# USB3SS0_ECC_AGGR register map
Vendor: Texas Instruments
Peripheral module from a debugger description file (folder am65x).
Registers are 32-bit, access not given, reset 0x0 unless marked. A register's access mark holds for its fields unless they carry their own. Offsets are as the file gives them; lines under a group give offsets from that group; [hi:lo] are bit positions; {n}, {i} and the like mark numbered series; 'fields as' and 'values as' point back to an identical list; <NAME> marks a mode.

## USB3SS0_ECC_AGGR
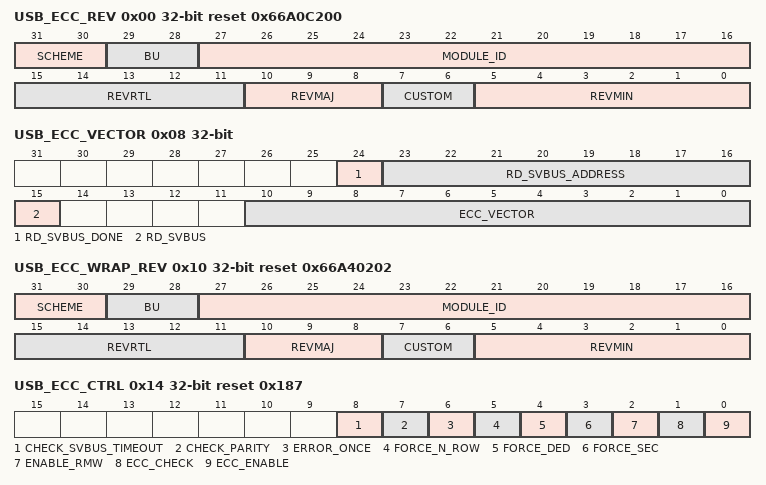
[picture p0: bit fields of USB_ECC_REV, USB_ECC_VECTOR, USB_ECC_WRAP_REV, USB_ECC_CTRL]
0x00 USB_ECC_REV ro reset 0x66A0C200 — Revision parameters
  [31:30] SCHEME
  [29:28] BU
  [27:16] MODULE_ID
  [15:11] REVRTL — RTL version
  [10:8] REVMAJ — Major version
  [7:6] CUSTOM — Custom version
  [5:0] REVMIN — Minor version
0x08 USB_ECC_VECTOR — ECC Vector Register
  [24] RD_SVBUS_DONE ro — Status to indicate if read on serial VBUS is complete
  [23:16] RD_SVBUS_ADDRESS rw — Read address
  [15] RD_SVBUS — Write 1 to trigger a read on the serial VBUS (access RW1S)
  [10:0] ECC_VECTOR rw — Value written to select the corresponding ECC RAM for control or status
0x0C USB_ECC_STAT ro reset 0x3 — Misc Status
  [10:0] NUM_RAMS — Indicates the number of RAMS serviced by the ECC aggregator
0x10 USB_ECC_WRAP_REV ro reset 0x66A40202 — Revision parameters
  fields as USB_ECC_REV
0x14 USB_ECC_CTRL rw reset 0x187 — ECC Control Register
  [8] CHECK_SVBUS_TIMEOUT — check for svbus timeout errors
  [7] CHECK_PARITY — check for parity errors
  [6] ERROR_ONCE — Force Error only once
  [5] FORCE_N_ROW — Force Error on any RAM read
  [4] FORCE_DED — Force Double Bit Error
  [3] FORCE_SEC — Force Single Bit Error
  [2] ENABLE_RMW
  [1] ECC_CHECK — Enable ECC check
  [0] ECC_ENABLE — Enable ECC
0x18 USB_ECC_ERR_CTRL1 rw — ECC Error Control1 Register
  [31:0] ECC_ROW — Row address where single or double-bit error needs to be applied. This is ignored if force_n_row is set
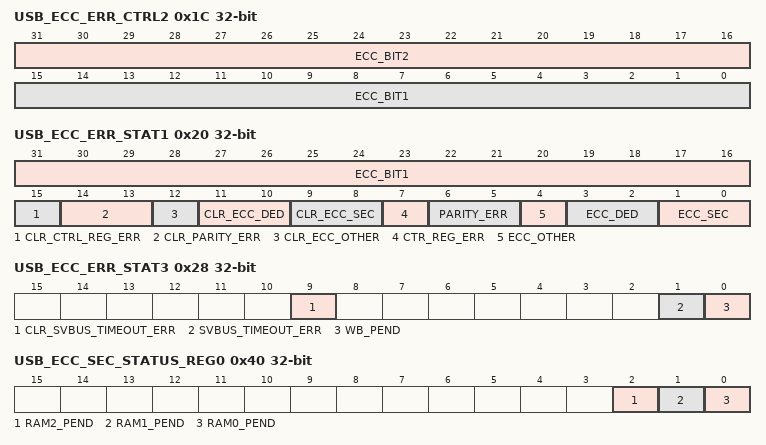
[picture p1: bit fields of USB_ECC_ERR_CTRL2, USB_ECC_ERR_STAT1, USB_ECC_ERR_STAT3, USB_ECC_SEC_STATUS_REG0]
0x1C USB_ECC_ERR_CTRL2 rw — ECC Error Control2 Register
  [31:16] ECC_BIT2 — Data bit that needs to be flipped if double bit error needs to be forced
  [15:0] ECC_BIT1 — Data bit that needs to be flipped when force_sec is set
0x20 USB_ECC_ERR_STAT1 — ECC Error Status1 Register
  [31:16] ECC_BIT1 ro — Data bit that corresponds to the single-bit error
  [15] CLR_CTRL_REG_ERR — Clear control reg error Error Status, one must also re write the contorl ergister itself to clear this (access RW1C)
  [14:13] CLR_PARITY_ERR rw — Clear parity Error Status
  [12] CLR_ECC_OTHER — Clear other Error Status (access RW1C)
  [11:10] CLR_ECC_DED rw — Clear Double Bit Error Status
  [9:8] CLR_ECC_SEC rw — Clear Single Bit Error Status
  [7] CTR_REG_ERR — control register error pending, Level interrupt (access RW1S)
  [6:5] PARITY_ERR — Level parity error Error Status (access RW1S)
  [4] ECC_OTHER — successive single-bit errors have occurred while a writeback is still pending, Level interrupt (access RW1S)
  [3:2] ECC_DED rw — Level Double Bit Error Status
  [1:0] ECC_SEC rw — Level Single Bit Error Status
0x24 USB_ECC_ERR_STAT2 ro — ECC Error Status2 Register
  [31:0] ECC_ROW — Row address where the single or double-bit error has occurred
0x28 USB_ECC_ERR_STAT3 — ECC Error Status3 Register
  [9] CLR_SVBUS_TIMEOUT_ERR — Clear svbus timeout Error Status (access RW1C)
  [1] SVBUS_TIMEOUT_ERR — Level svbus timeout error Error Status (access RW1S)
  [0] WB_PEND ro — delayed write back pending Status
0x3C USB_ECC_SEC_EOI_REG — EOI Register The EOI register is used to re-trigger the pulse interrupt signal to ensure that any nested interrupt events are serviced. The software interrupt handler must write to the EOI register at the end of the current interrupt processing routine, so that new events can re-trigger the pulse interrupt signal again. For level interrupt signals the EOI register is not functional and must not be used.
  [0] EOI_WR — EOI Register (access RW1S)
0x40 USB_ECC_SEC_STATUS_REG0 — Interrupt Status Register 0
  [2] RAM2_PEND — Interrupt Pending Status for ram2_pend (access RW1S)
  [1] RAM1_PEND — Interrupt Pending Status for ram1_pend (access RW1S)
  [0] RAM0_PEND — Interrupt Pending Status for ram0_pend (access RW1S)
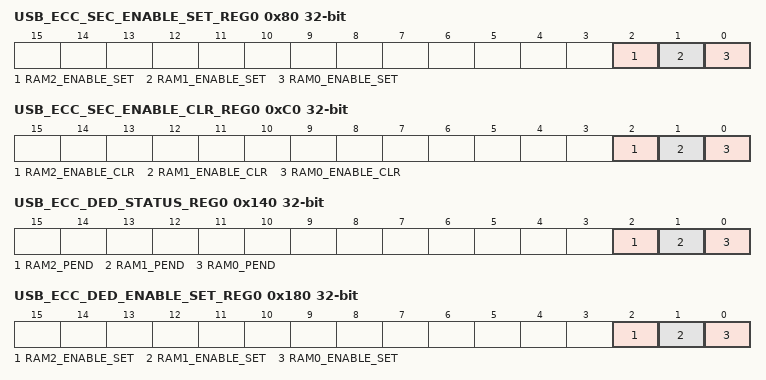
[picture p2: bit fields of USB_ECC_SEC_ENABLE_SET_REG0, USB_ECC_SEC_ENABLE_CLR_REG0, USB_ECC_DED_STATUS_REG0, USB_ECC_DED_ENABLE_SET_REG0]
0x80 USB_ECC_SEC_ENABLE_SET_REG0 — Interrupt Enable Set Register 0
  [2] RAM2_ENABLE_SET — Interrupt Enable Set Register for ram2_pend (access RW1S)
  [1] RAM1_ENABLE_SET — Interrupt Enable Set Register for ram1_pend (access RW1S)
  [0] RAM0_ENABLE_SET — Interrupt Enable Set Register for ram0_pend (access RW1S)
0xC0 USB_ECC_SEC_ENABLE_CLR_REG0 — Interrupt Enable Clear Register 0
  [2] RAM2_ENABLE_CLR — Interrupt Enable Clear Register for ram2_pend (access RW1C)
  [1] RAM1_ENABLE_CLR — Interrupt Enable Clear Register for ram1_pend (access RW1C)
  [0] RAM0_ENABLE_CLR — Interrupt Enable Clear Register for ram0_pend (access RW1C)
0x13C USB_ECC_DED_EOI_REG — EOI Register The EOI register is used to re-trigger the pulse interrupt signal to ensure that any nested interrupt events are serviced. The software interrupt handler must write to the EOI register at the end of the current interrupt processing routine, so that new events can re-trigger the pulse interrupt signal again. For level interrupt signals the EOI register is not functional and must not be used.
  [0] EOI_WR — EOI Register (access RW1S)
0x140 USB_ECC_DED_STATUS_REG0 — Interrupt Status Register 0
  fields as USB_ECC_SEC_STATUS_REG0
0x180 USB_ECC_DED_ENABLE_SET_REG0 — Interrupt Enable Set Register 0
  fields as USB_ECC_SEC_ENABLE_SET_REG0
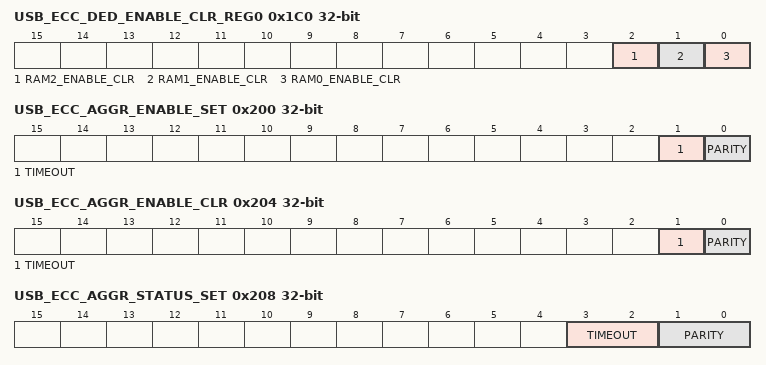
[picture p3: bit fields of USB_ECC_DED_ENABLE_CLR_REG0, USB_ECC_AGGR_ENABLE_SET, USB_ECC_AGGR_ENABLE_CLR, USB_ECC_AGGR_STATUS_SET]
0x1C0 USB_ECC_DED_ENABLE_CLR_REG0 — Interrupt Enable Clear Register 0
  fields as USB_ECC_SEC_ENABLE_CLR_REG0
0x200 USB_ECC_AGGR_ENABLE_SET — AGGR interrupt enable set Register
  [1] TIMEOUT — interrupt enable set for svbus timeout errors (access RW1S)
  [0] PARITY — interrupt enable set for parity errors (access RW1S)
0x204 USB_ECC_AGGR_ENABLE_CLR — AGGR interrupt enable clear Register
  [1] TIMEOUT — interrupt enable clear for svbus timeout errors (access RW1C)
  [0] PARITY — interrupt enable clear for parity errors (access RW1C)
0x208 USB_ECC_AGGR_STATUS_SET rw — AGGR interrupt status set Register
  [3:2] TIMEOUT — interrupt status set for svbus timeout errors
  [1:0] PARITY — interrupt status set for parity errors
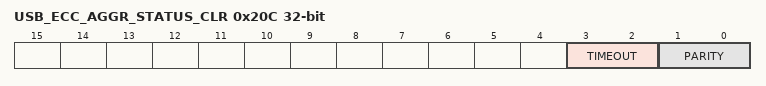
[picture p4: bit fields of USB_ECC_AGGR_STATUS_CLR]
0x20C USB_ECC_AGGR_STATUS_CLR rw — AGGR interrupt status clear Register
  [3:2] TIMEOUT — interrupt status clear for svbus timeout errors
  [1:0] PARITY — interrupt status clear for parity errors
